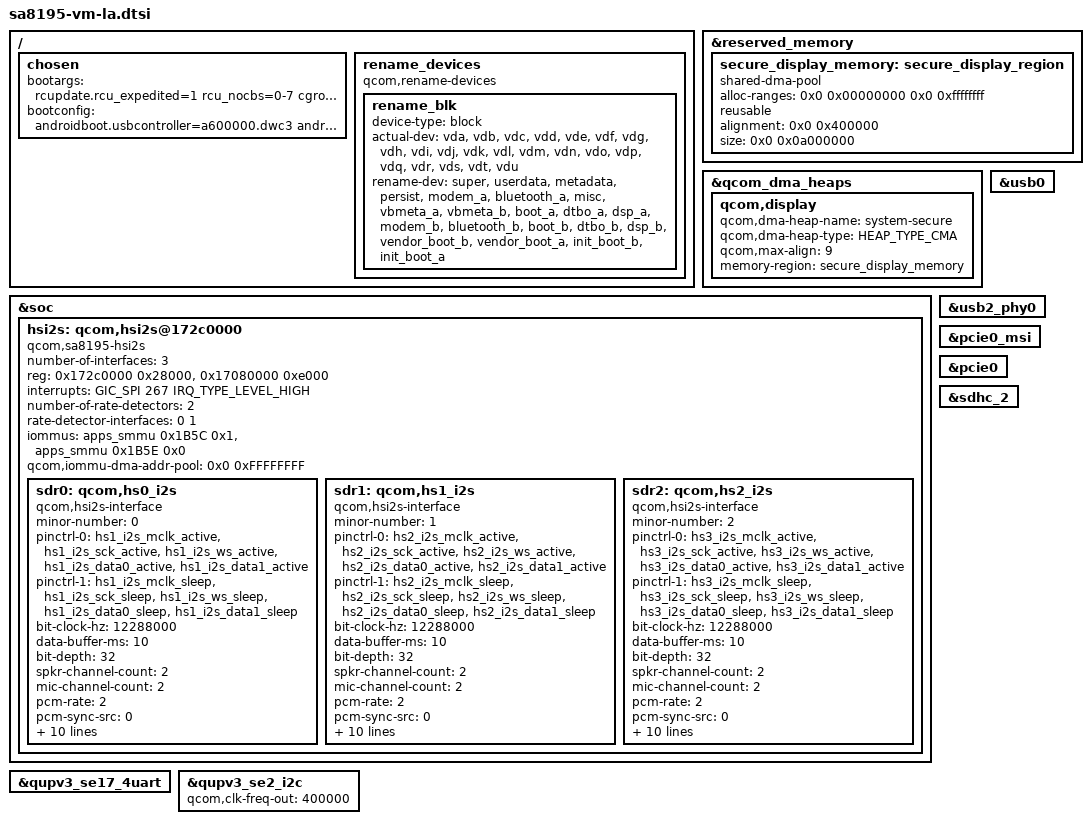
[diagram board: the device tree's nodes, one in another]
&reserved_memory {
	secure_display_memory: secure_display_region {
		compatible = "shared-dma-pool";
		alloc-ranges = <0x0 0x00000000 0x0 0xffffffff>;
		reusable;
		alignment = <0x0 0x400000>;
		size = <0x0 0x0a000000>;
	};
};

&qcom_dma_heaps {
	qcom,display {
		qcom,dma-heap-name = "system-secure";
		qcom,dma-heap-type = <HEAP_TYPE_CMA>;
		qcom,max-align = <9>;
		memory-region = <&secure_display_memory>;
	};
};

&soc {
	hsi2s: qcom,hsi2s@172c0000 {
		compatible = "qcom,sa8195-hsi2s", "qcom,hsi2s";
		number-of-interfaces = <3>;
		reg = <0x172c0000 0x28000>,
		      <0x17080000 0xe000>;
		reg-names = "lpa_if", "lpass_tcsr";
		interrupts = <GIC_SPI 267 IRQ_TYPE_LEVEL_HIGH>;
		number-of-rate-detectors = <2>;
		rate-detector-interfaces = <0 1>;
		iommus = <&apps_smmu 0x1B5C 0x1>,
			 <&apps_smmu 0x1B5E 0x0>;
		qcom,iommu-dma-addr-pool = <0x0 0xFFFFFFFF>;

		sdr0: qcom,hs0_i2s {
			compatible = "qcom,hsi2s-interface";
			minor-number = <0>;
			pinctrl-names = "default", "sleep";
			pinctrl-0 = <&hs1_i2s_mclk_active &hs1_i2s_sck_active
				     &hs1_i2s_ws_active &hs1_i2s_data0_active
				     &hs1_i2s_data1_active>;
			pinctrl-1 = <&hs1_i2s_mclk_sleep &hs1_i2s_sck_sleep
				     &hs1_i2s_ws_sleep &hs1_i2s_data0_sleep
				     &hs1_i2s_data1_sleep>;
			bit-clock-hz = <12288000>;
			data-buffer-ms = <10>;
			bit-depth = <32>;
			spkr-channel-count = <2>;
			mic-channel-count = <2>;
			pcm-rate = <2>;
			pcm-sync-src = <0>;
			aux-mode = <0>;
			rpcm-width = <1>;
			tpcm-width = <1>;
			enable-tdm = <1>;
			tdm-rate = <32>;
			tdm-rpcm-width = <16>;
			tdm-tpcm-width = <16>;
			tdm-sync-delay = <2>;
			tdm-inv-sync = <0>;
			pcm-lane-config = <1>;
		};

		sdr1: qcom,hs1_i2s {
			compatible = "qcom,hsi2s-interface";
			minor-number = <1>;
			pinctrl-names = "default", "sleep";
			pinctrl-0 = <&hs2_i2s_mclk_active &hs2_i2s_sck_active
				     &hs2_i2s_ws_active &hs2_i2s_data0_active
				     &hs2_i2s_data1_active>;
			pinctrl-1 = <&hs2_i2s_mclk_sleep &hs2_i2s_sck_sleep
				     &hs2_i2s_ws_sleep &hs2_i2s_data0_sleep
				     &hs2_i2s_data1_sleep>;
			bit-clock-hz = <12288000>;
			data-buffer-ms = <10>;
			bit-depth = <32>;
			spkr-channel-count = <2>;
			mic-channel-count = <2>;
			pcm-rate = <2>;
			pcm-sync-src = <0>;
			aux-mode = <0>;
			rpcm-width = <1>;
			tpcm-width = <1>;
			enable-tdm = <1>;
			tdm-rate = <32>;
			tdm-rpcm-width = <16>;
			tdm-tpcm-width = <16>;
			tdm-sync-delay = <2>;
			tdm-inv-sync = <0>;
			pcm-lane-config = <1>;
		};

		sdr2: qcom,hs2_i2s {
			compatible = "qcom,hsi2s-interface";
			minor-number = <2>;
			pinctrl-names = "default", "sleep";
			pinctrl-0 = <&hs3_i2s_mclk_active &hs3_i2s_sck_active
				     &hs3_i2s_ws_active &hs3_i2s_data0_active
				     &hs3_i2s_data1_active>;
			pinctrl-1 = <&hs3_i2s_mclk_sleep &hs3_i2s_sck_sleep
				     &hs3_i2s_ws_sleep &hs3_i2s_data0_sleep
				     &hs3_i2s_data1_sleep>;
			bit-clock-hz = <12288000>;
			data-buffer-ms = <10>;
			bit-depth = <32>;
			spkr-channel-count = <2>;
			mic-channel-count = <2>;
			pcm-rate = <2>;
			pcm-sync-src = <0>;
			aux-mode = <0>;
			rpcm-width = <1>;
			tpcm-width = <1>;
			enable-tdm = <1>;
			tdm-rate = <32>;
			tdm-rpcm-width = <16>;
			tdm-tpcm-width = <16>;
			tdm-sync-delay = <2>;
			tdm-inv-sync = <0>;
			pcm-lane-config = <1>;
		};
	};
};

/ {
	chosen {
		bootargs = "rcupdate.rcu_expedited=1 rcu_nocbs=0-7 cgroup.memory=nokmem,nosocket kpti=0 qcom_dma_heaps.enable_bitstream_contig_heap=y arm64.nopauth kasan=off msm_show_resume_irq.debug_mask=1 ";
		bootconfig = "androidboot.usbcontroller=a600000.dwc3 androidboot.fstab_suffix=gen3.qcom androidboot.dtbo_idx=12";
	};

	rename_devices: rename_devices {
		compatible = "qcom,rename-devices";
		rename_blk: rename_blk {
			device-type = "block";
			actual-dev = "vda", "vdb", "vdc",
					"vdd", "vde", "vdf",
					"vdg", "vdh", "vdi",
					"vdj", "vdk", "vdl",
					"vdm", "vdn", "vdo",
					"vdp", "vdq", "vdr",
					"vds", "vdt", "vdu";
			rename-dev = "super", "userdata", "metadata",
					"persist", "modem_a","bluetooth_a",
					"misc", "vbmeta_a", "vbmeta_b",
					"boot_a", "dtbo_a","dsp_a",
					"modem_b", "bluetooth_b", "boot_b",
					"dtbo_b", "dsp_b", "vendor_boot_b",
					"vendor_boot_a", "init_boot_b", "init_boot_a";
		};
	};
};

&usb0 {
	status = "ok";
};

&usb2_phy0 {
	status = "ok";
};

&qupv3_se17_4uart {
	status = "ok";
};

&pcie0_msi {
	status = "ok";
};

&pcie0 {
	status = "ok";
};

&sdhc_2 {
	status = "ok";
};

&qupv3_se2_i2c {
	qcom,clk-freq-out = <400000>;
	status = "ok";
};
